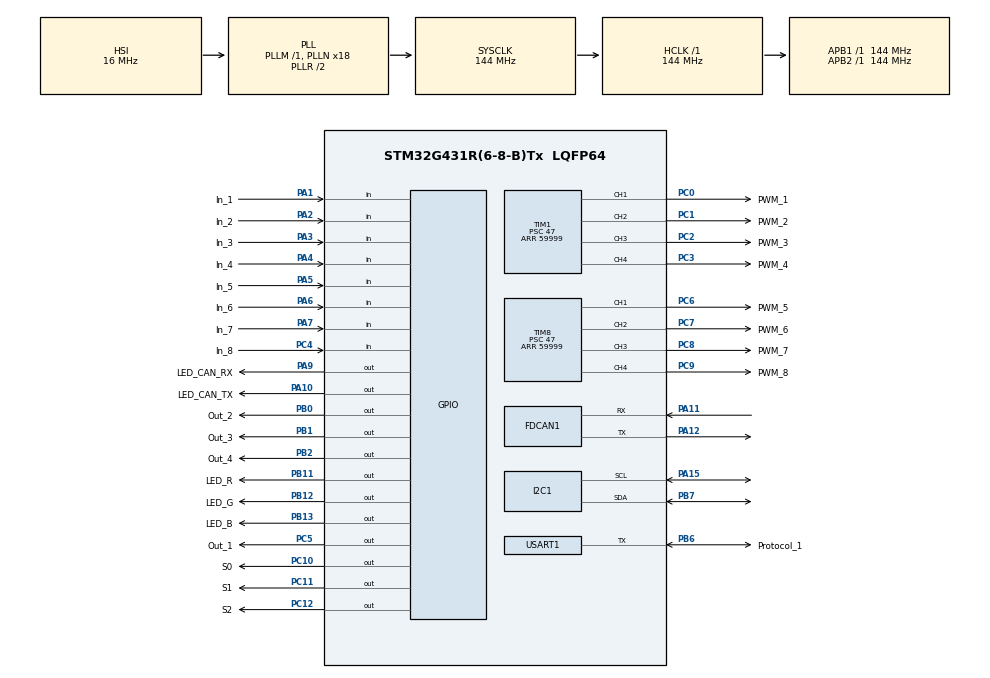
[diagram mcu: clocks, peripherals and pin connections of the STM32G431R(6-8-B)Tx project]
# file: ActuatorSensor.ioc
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Dma.Request0=USART1_RX
Dma.USART1_RX.0.Direction=DMA_PERIPH_TO_MEMORY
Dma.USART1_RX.0.EventEnable=DISABLE
Dma.USART1_RX.0.Instance=DMA1_Channel1
Dma.USART1_RX.0.MemDataAlignment=DMA_MDATAALIGN_BYTE
Dma.USART1_RX.0.MemInc=DMA_MINC_ENABLE
Dma.USART1_RX.0.Mode=DMA_NORMAL
Dma.USART1_RX.0.PeriphDataAlignment=DMA_PDATAALIGN_BYTE
Dma.USART1_RX.0.PeriphInc=DMA_PINC_DISABLE
Dma.USART1_RX.0.Polarity=HAL_DMAMUX_REQ_GEN_RISING
Dma.USART1_RX.0.Priority=DMA_PRIORITY_LOW
Dma.USART1_RX.0.RequestNumber=1
Dma.USART1_RX.0.SignalID=NONE
Dma.USART1_RX.0.SyncEnable=DISABLE
Dma.USART1_RX.0.SyncPolarity=HAL_DMAMUX_SYNC_NO_EVENT
Dma.USART1_RX.0.SyncRequestNumber=1
Dma.USART1_RX.0.SyncSignalID=NONE
FDCAN1.AutoRetransmission=ENABLE
FDCAN1.CalculateBaudRateNominal=1000000
FDCAN1.CalculateTimeBitNominal=1000
FDCAN1.CalculateTimeQuantumNominal=6.944444444444445
FDCAN1.DataPrescaler=1
FDCAN1.DataSyncJumpWidth=8
FDCAN1.DataTimeSeg1=9
FDCAN1.DataTimeSeg2=8
FDCAN1.FrameFormat=FDCAN_FRAME_FD_NO_BRS
FDCAN1.NominalPrescaler=1
FDCAN1.NominalSyncJumpWidth=19
FDCAN1.NominalTimeSeg1=124
FDCAN1.NominalTimeSeg2=19
FDCAN1.StdFiltersNbr=1
I2C1.Timing=0x20B0D9FF
Mcu.Family=STM32G4
Mcu.Name=STM32G431R(6-8-B)Tx
Mcu.Package=LQFP64
NVIC.DMA1_Channel1_IRQn=true\:0\:0\:false\:false\:true\:false\:true\:true
NVIC.FDCAN1_IT0_IRQn=true\:0\:0\:true\:false\:true\:true\:true\:true
NVIC.PriorityGroup=NVIC_PRIORITYGROUP_4
NVIC.TIM6_DAC_IRQn=true\:0\:0\:true\:false\:true\:true\:true\:true
NVIC.TIM7_IRQn=true\:0\:0\:true\:false\:true\:true\:true\:true
NVIC.USART1_IRQn=true\:0\:0\:false\:false\:true\:true\:true\:true
PA1.GPIO_Label=In_1
PA1.Signal=GPIO_Input
PA10.GPIO_Label=LED_CAN_TX
PA10.Signal=GPIO_Output
PA11.Mode=FDCAN_Activate
PA11.Signal=FDCAN1_RX
PA12.Mode=FDCAN_Activate
PA12.Signal=FDCAN1_TX
PA13.Mode=Trace_Asynchronous_SW
PA13.Signal=SYS_JTMS-SWDIO
PA14.Mode=Trace_Asynchronous_SW
PA14.Signal=SYS_JTCK-SWCLK
PA15.Mode=I2C
PA15.Signal=I2C1_SCL
PA2.GPIO_Label=In_2
PA2.Signal=GPIO_Input
PA3.GPIO_Label=In_3
PA3.Signal=GPIO_Input
PA4.GPIO_Label=In_4
PA4.Signal=GPIO_Input
PA5.GPIO_Label=In_5
PA5.Signal=GPIO_Input
PA6.GPIO_Label=In_6
PA6.Signal=GPIO_Input
PA7.GPIO_Label=In_7
PA7.Signal=GPIO_Input
PA9.GPIO_Label=LED_CAN_RX
PA9.Signal=GPIO_Output
PB0.GPIO_Label=Out_2
PB0.Signal=GPIO_Output
PB1.GPIO_Label=Out_3
PB1.Signal=GPIO_Output
PB11.GPIO_Label=LED_R
PB11.Signal=GPIO_Output
PB12.GPIO_Label=LED_G
PB12.Signal=GPIO_Output
PB13.GPIO_Label=LED_B
PB13.Signal=GPIO_Output
PB2.GPIO_Label=Out_4
PB2.Signal=GPIO_Output
PB3.Mode=Trace_Asynchronous_SW
PB3.Signal=SYS_JTDO-SWO
PB6.GPIO_Label=Protocol_1
PB6.GPIO_ModeDefaultOD=GPIO_MODE_AF_OD
PB6.GPIO_PuPd=GPIO_NOPULL
PB6.Mode=Half_duplex(single_wire_mode)
PB6.Signal=USART1_TX
PB7.Mode=I2C
PB7.Signal=I2C1_SDA
PC0.GPIO_Label=PWM_1
PC0.Signal=S_TIM1_CH1
PC1.GPIO_Label=PWM_2
PC1.Signal=S_TIM1_CH2
PC10.GPIO_Label=S0
PC10.Signal=GPIO_Output
PC11.GPIO_Label=S1
PC11.Signal=GPIO_Output
PC12.GPIO_Label=S2
PC12.Signal=GPIO_Output
PC2.GPIO_Label=PWM_3
PC2.Signal=S_TIM1_CH3
PC3.GPIO_Label=PWM_4
PC3.Signal=S_TIM1_CH4
PC4.GPIO_Label=In_8
PC4.Signal=GPIO_Input
PC5.GPIO_Label=Out_1
PC5.Signal=GPIO_Output
PC6.GPIO_Label=PWM_5
PC6.Signal=S_TIM8_CH1
PC7.GPIO_Label=PWM_6
PC7.Signal=S_TIM8_CH2
PC8.GPIO_Label=PWM_7
PC8.Signal=S_TIM8_CH3
PC9.GPIO_Label=PWM_8
PC9.Signal=S_TIM8_CH4
ProjectManager.HeapSize=0x200
ProjectManager.StackSize=0x400
ProjectManager.TargetToolchain=STM32CubeIDE
RCC.ADC12Freq_Value=144000000
RCC.AHBFreq_Value=144000000
RCC.APB1Freq_Value=144000000
RCC.APB1TimFreq_Value=144000000
RCC.APB2Freq_Value=144000000
RCC.APB2TimFreq_Value=144000000
RCC.CortexFreq_Value=144000000
RCC.EXTERNAL_CLOCK_VALUE=12288000
RCC.HCLKFreq_Value=144000000
RCC.HSE_VALUE=8000000
RCC.HSI48_VALUE=48000000
RCC.HSI_VALUE=16000000
RCC.LSE_VALUE=32768
RCC.PLLN=18
RCC.SYSCLKFreq_VALUE=144000000
RCC.SYSCLKSource=RCC_SYSCLKSOURCE_PLLCLK
RCC.USBFreq_Value=144000000
RCC.VCOOutputFreq_Value=288000000
SH.S_TIM1_CH1.0=TIM1_CH1,PWM Generation1 CH1
SH.S_TIM1_CH2.0=TIM1_CH2,PWM Generation2 CH2
SH.S_TIM1_CH3.0=TIM1_CH3,PWM Generation3 CH3
SH.S_TIM1_CH4.0=TIM1_CH4,PWM Generation4 CH4
SH.S_TIM8_CH1.0=TIM8_CH1,PWM Generation1 CH1
SH.S_TIM8_CH2.0=TIM8_CH2,PWM Generation2 CH2
SH.S_TIM8_CH3.0=TIM8_CH3,PWM Generation3 CH3
SH.S_TIM8_CH4.0=TIM8_CH4,PWM Generation4 CH4
TIM1.Channel-PWM\ Generation1\ CH1=TIM_CHANNEL_1
TIM1.Channel-PWM\ Generation2\ CH2=TIM_CHANNEL_2
TIM1.Channel-PWM\ Generation3\ CH3=TIM_CHANNEL_3
TIM1.Channel-PWM\ Generation4\ CH4=TIM_CHANNEL_4
TIM1.PeriodNoDither=59999
TIM1.Prescaler=47
TIM16.PeriodNoDither=47999
TIM16.Prescaler=5
TIM6.PeriodNoDither=59999
TIM6.Prescaler=23
TIM7.PeriodNoDither=59999
TIM8.Channel-PWM\ Generation1\ CH1=TIM_CHANNEL_1
TIM8.Channel-PWM\ Generation2\ CH2=TIM_CHANNEL_2
TIM8.Channel-PWM\ Generation3\ CH3=TIM_CHANNEL_3
TIM8.Channel-PWM\ Generation4\ CH4=TIM_CHANNEL_4
TIM8.PeriodNoDither=59999
TIM8.Prescaler=47
USART1.BaudRate=57600
USART1.VirtualMode-Half_duplex(single_wire_mode)=VM_ASYNC
VP_SYS_VS_DBSignals.Mode=DisableDeadBatterySignals
VP_TIM16_VS_ClockSourceINT.Mode=Enable_Timer
VP_TIM6_VS_ClockSourceINT.Mode=Enable_Timer
VP_TIM7_VS_ClockSourceINT.Mode=Enable_Timer
board=custom

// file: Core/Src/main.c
/* USER CODE BEGIN Header */
/**
  ******************************************************************************
  * @file           : main.c
  * @brief          : Main program body
  ******************************************************************************
  * @attention
  *
  * Copyright (c) 2024 STMicroelectronics.
  * All rights reserved.
  *
  * This software is licensed under terms that can be found in the LICENSE file
  * in the root directory of this software component.
  * If no LICENSE file comes with this software, it is provided AS-IS.
  *
  ******************************************************************************
  */
/* USER CODE END Header */
#include "main.h"

/* USER CODE BEGIN Includes */
//#include "rc_servo.h"
#include "ax_servo.h"
/* USER CODE END Includes */

FDCAN_HandleTypeDef hfdcan1;

I2C_HandleTypeDef hi2c1;

TIM_HandleTypeDef htim1;
TIM_HandleTypeDef htim6;
TIM_HandleTypeDef htim7;
TIM_HandleTypeDef htim8;
TIM_HandleTypeDef htim16;

UART_HandleTypeDef huart1;
DMA_HandleTypeDef hdma_usart1_rx;

void SystemClock_Config(void);
static void MX_GPIO_Init(void);
static void MX_DMA_Init(void);
static void MX_FDCAN1_Init(void);
static void MX_I2C1_Init(void);
static void MX_TIM1_Init(void);
static void MX_TIM8_Init(void);
static void MX_USART1_UART_Init(void);
static void MX_TIM6_Init(void);
static void MX_TIM7_Init(void);
static void MX_TIM16_Init(void);

int main(void)
{

  /* MCU Configuration--------------------------------------------------------*/

  /* Reset of all peripherals, Initializes the Flash interface and the Systick. */
  HAL_Init();

  /* Configure the system clock */
  SystemClock_Config();

  /* Initialize all configured peripherals */
  MX_GPIO_Init();
  MX_DMA_Init();
  MX_FDCAN1_Init();
  MX_I2C1_Init();
  MX_TIM1_Init();
  MX_TIM8_Init();
  MX_USART1_UART_Init();
  MX_TIM6_Init();
  MX_TIM7_Init();
  MX_TIM16_Init();
  /* USER CODE BEGIN 2 */
//  HAL_NVIC_SetPriority()
  FDCAN_Init(&hfdcan1);

  HAL_TIM_Base_Start_IT(&htim6); // Servo moving checking
  HAL_TIM_Base_Start_IT(&htim7); // Input pin states checking

//  Set_ADC_Channel(0);GRIPGRIP_GAIN_GAIN
//  HAL_ADCEx_Calibration_Start(&hadc1, ADC_SINGLE_ENDED);
//  HAL_ADC_Start_DMA(&hadc1, &adc_output, 1);

//  Init_RC_Servo(0, &htim1, TIM_CHANNEL_1);
//  Init_RC_Servo(1, &htim1, TIM_CHANNEL_2);
//  Init_RC_Servo(2, &htim1, TIM_CHANNEL_3);
//  Init_RC_Servo(3, &htim1, TIM_CHANNEL_4);
//
//  Init_RC_Servo(4, &htim8, TIM_CHANNEL_1);
//  Init_RC_Servo(5, &htim8, TIM_CHANNEL_2);
//  Init_RC_Servo(6, &htim8, TIM_CHANNEL_3);
//  Init_RC_Servo(7, &htim8, TIM_CHANNEL_4);

  /* USER CODE END 2 */

  /* Infinite loop */
  /* USER CODE BEGIN WHILE */
//  uint8_t some_status = 0;
  while (1)
  {
//	if (send_status == HAL_OK)
//	{
//	  send_status = HAL_ERROR;
//	  HAL_GPIO_TogglePin(LED_CAN_TX_GPIO_Port, LED_CAN_TX_Pin);
//	  some_status = 1;
//	}
//	else
//	{
//	  HAL_GPIO_WritePin(LED_CAN_TX_GPIO_Port, LED_CAN_TX_Pin, GPIO_PIN_RESET);
//	}
//
//	if (receive_status == HAL_OK)
//	{
//	  receive_status = HAL_ERROR;
//	  HAL_GPIO_TogglePin(LED_CAN_RX_GPIO_Port, LED_CAN_RX_Pin);
//	  some_status = 1;
//	}
//	else
//	{
//      HAL_GPIO_WritePin(LED_CAN_RX_GPIO_Port, LED_CAN_RX_Pin, GPIO_PIN_RESET);
//	}
//
//	if (some_status)
//	{
//	  some_status = 0;
//	  HAL_Delay(50);
//	}
//	  HAL_Delay(1000);
//
//	  Set_Angle(id, 0);
//
//	  HAL_Delay(1000);
//	if (rx_set) {
//		rx_set = 0;
//		HAL_Delay(500);
//		HAL_GPIO_WritePin(LED_G_GPIO_Port, LED_G_Pin, GPIO_PIN_RESET);
//	}
    /* USER CODE END WHILE */

  }
}

void SystemClock_Config(void)
{
  RCC_OscInitTypeDef RCC_OscInitStruct = {0};
  RCC_ClkInitTypeDef RCC_ClkInitStruct = {0};

  /** Configure the main internal regulator output voltage
  */
  HAL_PWREx_ControlVoltageScaling(PWR_REGULATOR_VOLTAGE_SCALE1);

  /** Initializes the RCC Oscillators according to the specified parameters
  * in the RCC_OscInitTypeDef structure.
  */
  RCC_OscInitStruct.OscillatorType = RCC_OSCILLATORTYPE_HSI;
  RCC_OscInitStruct.HSIState = RCC_HSI_ON;
  RCC_OscInitStruct.HSICalibrationValue = RCC_HSICALIBRATION_DEFAULT;
  RCC_OscInitStruct.PLL.PLLState = RCC_PLL_ON;
  RCC_OscInitStruct.PLL.PLLSource = RCC_PLLSOURCE_HSI;
  RCC_OscInitStruct.PLL.PLLM = RCC_PLLM_DIV1;
  RCC_OscInitStruct.PLL.PLLN = 18;
  RCC_OscInitStruct.PLL.PLLP = RCC_PLLP_DIV2;
  RCC_OscInitStruct.PLL.PLLQ = RCC_PLLQ_DIV2;
  RCC_OscInitStruct.PLL.PLLR = RCC_PLLR_DIV2;
  if (HAL_RCC_OscConfig(&RCC_OscInitStruct) != HAL_OK)
  {
    Error_Handler();
  }

  /** Initializes the CPU, AHB and APB buses clocks
  */
  RCC_ClkInitStruct.ClockType = RCC_CLOCKTYPE_HCLK|RCC_CLOCKTYPE_SYSCLK
                              |RCC_CLOCKTYPE_PCLK1|RCC_CLOCKTYPE_PCLK2;
  RCC_ClkInitStruct.SYSCLKSource = RCC_SYSCLKSOURCE_PLLCLK;
  RCC_ClkInitStruct.AHBCLKDivider = RCC_SYSCLK_DIV1;
  RCC_ClkInitStruct.APB1CLKDivider = RCC_HCLK_DIV1;
  RCC_ClkInitStruct.APB2CLKDivider = RCC_HCLK_DIV1;

  if (HAL_RCC_ClockConfig(&RCC_ClkInitStruct, FLASH_LATENCY_4) != HAL_OK)
  {
    Error_Handler();
  }
}

static void MX_FDCAN1_Init(void)
{

  hfdcan1.Instance = FDCAN1;
  hfdcan1.Init.ClockDivider = FDCAN_CLOCK_DIV1;
  hfdcan1.Init.FrameFormat = FDCAN_FRAME_FD_NO_BRS;
  hfdcan1.Init.Mode = FDCAN_MODE_NORMAL;
  hfdcan1.Init.AutoRetransmission = ENABLE;
  hfdcan1.Init.TransmitPause = DISABLE;
  hfdcan1.Init.ProtocolException = DISABLE;
  hfdcan1.Init.NominalPrescaler = 1;
  hfdcan1.Init.NominalSyncJumpWidth = 19;
  hfdcan1.Init.NominalTimeSeg1 = 124;
  hfdcan1.Init.NominalTimeSeg2 = 19;
  hfdcan1.Init.DataPrescaler = 1;
  hfdcan1.Init.DataSyncJumpWidth = 8;
  hfdcan1.Init.DataTimeSeg1 = 9;
  hfdcan1.Init.DataTimeSeg2 = 8;
  hfdcan1.Init.StdFiltersNbr = 1;
  hfdcan1.Init.ExtFiltersNbr = 0;
  hfdcan1.Init.TxFifoQueueMode = FDCAN_TX_FIFO_OPERATION;
  if (HAL_FDCAN_Init(&hfdcan1) != HAL_OK)
  {
    Error_Handler();
  }

}

static void MX_I2C1_Init(void)
{

  hi2c1.Instance = I2C1;
  hi2c1.Init.Timing = 0x20B0D9FF;
  hi2c1.Init.OwnAddress1 = 0;
  hi2c1.Init.AddressingMode = I2C_ADDRESSINGMODE_7BIT;
  hi2c1.Init.DualAddressMode = I2C_DUALADDRESS_DISABLE;
  hi2c1.Init.OwnAddress2 = 0;
  hi2c1.Init.OwnAddress2Masks = I2C_OA2_NOMASK;
  hi2c1.Init.GeneralCallMode = I2C_GENERALCALL_DISABLE;
  hi2c1.Init.NoStretchMode = I2C_NOSTRETCH_DISABLE;
  if (HAL_I2C_Init(&hi2c1) != HAL_OK)
  {
    Error_Handler();
  }

  /** Configure Analogue filter
  */
  if (HAL_I2CEx_ConfigAnalogFilter(&hi2c1, I2C_ANALOGFILTER_ENABLE) != HAL_OK)
  {
    Error_Handler();
  }

  /** Configure Digital filter
  */
  if (HAL_I2CEx_ConfigDigitalFilter(&hi2c1, 0) != HAL_OK)
  {
    Error_Handler();
  }

}

static void MX_TIM1_Init(void)
{

  TIM_MasterConfigTypeDef sMasterConfig = {0};
  TIM_OC_InitTypeDef sConfigOC = {0};
  TIM_BreakDeadTimeConfigTypeDef sBreakDeadTimeConfig = {0};

  htim1.Instance = TIM1;
  htim1.Init.Prescaler = 47;
  htim1.Init.CounterMode = TIM_COUNTERMODE_UP;
  htim1.Init.Period = 59999;
  htim1.Init.ClockDivision = TIM_CLOCKDIVISION_DIV1;
  htim1.Init.RepetitionCounter = 0;
  htim1.Init.AutoReloadPreload = TIM_AUTORELOAD_PRELOAD_DISABLE;
  if (HAL_TIM_PWM_Init(&htim1) != HAL_OK)
  {
    Error_Handler();
  }
  sMasterConfig.MasterOutputTrigger = TIM_TRGO_RESET;
  sMasterConfig.MasterOutputTrigger2 = TIM_TRGO2_RESET;
  sMasterConfig.MasterSlaveMode = TIM_MASTERSLAVEMODE_DISABLE;
  if (HAL_TIMEx_MasterConfigSynchronization(&htim1, &sMasterConfig) != HAL_OK)
  {
    Error_Handler();
  }
  sConfigOC.OCMode = TIM_OCMODE_PWM1;
  sConfigOC.Pulse = 0;
  sConfigOC.OCPolarity = TIM_OCPOLARITY_HIGH;
  sConfigOC.OCNPolarity = TIM_OCNPOLARITY_HIGH;
  sConfigOC.OCFastMode = TIM_OCFAST_DISABLE;
  sConfigOC.OCIdleState = TIM_OCIDLESTATE_RESET;
  sConfigOC.OCNIdleState = TIM_OCNIDLESTATE_RESET;
  if (HAL_TIM_PWM_ConfigChannel(&htim1, &sConfigOC, TIM_CHANNEL_1) != HAL_OK)
  {
    Error_Handler();
  }
  if (HAL_TIM_PWM_ConfigChannel(&htim1, &sConfigOC, TIM_CHANNEL_2) != HAL_OK)
  {
    Error_Handler();
  }
  if (HAL_TIM_PWM_ConfigChannel(&htim1, &sConfigOC, TIM_CHANNEL_3) != HAL_OK)
  {
    Error_Handler();
  }
  if (HAL_TIM_PWM_ConfigChannel(&htim1, &sConfigOC, TIM_CHANNEL_4) != HAL_OK)
  {
    Error_Handler();
  }
  sBreakDeadTimeConfig.OffStateRunMode = TIM_OSSR_DISABLE;
  sBreakDeadTimeConfig.OffStateIDLEMode = TIM_OSSI_DISABLE;
  sBreakDeadTimeConfig.LockLevel = TIM_LOCKLEVEL_OFF;
  sBreakDeadTimeConfig.DeadTime = 0;
  sBreakDeadTimeConfig.BreakState = TIM_BREAK_DISABLE;
  sBreakDeadTimeConfig.BreakPolarity = TIM_BREAKPOLARITY_HIGH;
  sBreakDeadTimeConfig.BreakFilter = 0;
  sBreakDeadTimeConfig.BreakAFMode = TIM_BREAK_AFMODE_INPUT;
  sBreakDeadTimeConfig.Break2State = TIM_BREAK2_DISABLE;
  sBreakDeadTimeConfig.Break2Polarity = TIM_BREAK2POLARITY_HIGH;
  sBreakDeadTimeConfig.Break2Filter = 0;
  sBreakDeadTimeConfig.Break2AFMode = TIM_BREAK_AFMODE_INPUT;
  sBreakDeadTimeConfig.AutomaticOutput = TIM_AUTOMATICOUTPUT_DISABLE;
  if (HAL_TIMEx_ConfigBreakDeadTime(&htim1, &sBreakDeadTimeConfig) != HAL_OK)
  {
    Error_Handler();
  }
  HAL_TIM_MspPostInit(&htim1);

}

static void MX_TIM6_Init(void)
{

  TIM_MasterConfigTypeDef sMasterConfig = {0};

  htim6.Instance = TIM6;
  htim6.Init.Prescaler = 23;
  htim6.Init.CounterMode = TIM_COUNTERMODE_UP;
  htim6.Init.Period = 59999;
  htim6.Init.AutoReloadPreload = TIM_AUTORELOAD_PRELOAD_DISABLE;
  if (HAL_TIM_Base_Init(&htim6) != HAL_OK)
  {
    Error_Handler();
  }
  sMasterConfig.MasterOutputTrigger = TIM_TRGO_RESET;
  sMasterConfig.MasterSlaveMode = TIM_MASTERSLAVEMODE_DISABLE;
  if (HAL_TIMEx_MasterConfigSynchronization(&htim6, &sMasterConfig) != HAL_OK)
  {
    Error_Handler();
  }

}

static void MX_TIM7_Init(void)
{

  TIM_MasterConfigTypeDef sMasterConfig = {0};

  htim7.Instance = TIM7;
  htim7.Init.Prescaler = 0;
  htim7.Init.CounterMode = TIM_COUNTERMODE_UP;
  htim7.Init.Period = 59999;
  htim7.Init.AutoReloadPreload = TIM_AUTORELOAD_PRELOAD_DISABLE;
  if (HAL_TIM_Base_Init(&htim7) != HAL_OK)
  {
    Error_Handler();
  }
  sMasterConfig.MasterOutputTrigger = TIM_TRGO_RESET;
  sMasterConfig.MasterSlaveMode = TIM_MASTERSLAVEMODE_DISABLE;
  if (HAL_TIMEx_MasterConfigSynchronization(&htim7, &sMasterConfig) != HAL_OK)
  {
    Error_Handler();
  }

}

static void MX_TIM8_Init(void)
{

  TIM_MasterConfigTypeDef sMasterConfig = {0};
  TIM_OC_InitTypeDef sConfigOC = {0};
  TIM_BreakDeadTimeConfigTypeDef sBreakDeadTimeConfig = {0};

  htim8.Instance = TIM8;
  htim8.Init.Prescaler = 47;
  htim8.Init.CounterMode = TIM_COUNTERMODE_UP;
  htim8.Init.Period = 59999;
  htim8.Init.ClockDivision = TIM_CLOCKDIVISION_DIV1;
  htim8.Init.RepetitionCounter = 0;
  htim8.Init.AutoReloadPreload = TIM_AUTORELOAD_PRELOAD_DISABLE;
  if (HAL_TIM_PWM_Init(&htim8) != HAL_OK)
  {
    Error_Handler();
  }
  sMasterConfig.MasterOutputTrigger = TIM_TRGO_RESET;
  sMasterConfig.MasterOutputTrigger2 = TIM_TRGO2_RESET;
  sMasterConfig.MasterSlaveMode = TIM_MASTERSLAVEMODE_DISABLE;
  if (HAL_TIMEx_MasterConfigSynchronization(&htim8, &sMasterConfig) != HAL_OK)
  {
    Error_Handler();
  }
  sConfigOC.OCMode = TIM_OCMODE_PWM1;
  sConfigOC.Pulse = 0;
  sConfigOC.OCPolarity = TIM_OCPOLARITY_HIGH;
  sConfigOC.OCNPolarity = TIM_OCNPOLARITY_HIGH;
  sConfigOC.OCFastMode = TIM_OCFAST_DISABLE;
  sConfigOC.OCIdleState = TIM_OCIDLESTATE_RESET;
  sConfigOC.OCNIdleState = TIM_OCNIDLESTATE_RESET;
  if (HAL_TIM_PWM_ConfigChannel(&htim8, &sConfigOC, TIM_CHANNEL_1) != HAL_OK)
  {
    Error_Handler();
  }
  if (HAL_TIM_PWM_ConfigChannel(&htim8, &sConfigOC, TIM_CHANNEL_2) != HAL_OK)
  {
    Error_Handler();
  }
  if (HAL_TIM_PWM_ConfigChannel(&htim8, &sConfigOC, TIM_CHANNEL_3) != HAL_OK)
  {
    Error_Handler();
  }
  if (HAL_TIM_PWM_ConfigChannel(&htim8, &sConfigOC, TIM_CHANNEL_4) != HAL_OK)
  {
    Error_Handler();
  }
  sBreakDeadTimeConfig.OffStateRunMode = TIM_OSSR_DISABLE;
  sBreakDeadTimeConfig.OffStateIDLEMode = TIM_OSSI_DISABLE;
  sBreakDeadTimeConfig.LockLevel = TIM_LOCKLEVEL_OFF;
  sBreakDeadTimeConfig.DeadTime = 0;
  sBreakDeadTimeConfig.BreakState = TIM_BREAK_DISABLE;
  sBreakDeadTimeConfig.BreakPolarity = TIM_BREAKPOLARITY_HIGH;
  sBreakDeadTimeConfig.BreakFilter = 0;
  sBreakDeadTimeConfig.BreakAFMode = TIM_BREAK_AFMODE_INPUT;
  sBreakDeadTimeConfig.Break2State = TIM_BREAK2_DISABLE;
  sBreakDeadTimeConfig.Break2Polarity = TIM_BREAK2POLARITY_HIGH;
  sBreakDeadTimeConfig.Break2Filter = 0;
  sBreakDeadTimeConfig.Break2AFMode = TIM_BREAK_AFMODE_INPUT;
  sBreakDeadTimeConfig.AutomaticOutput = TIM_AUTOMATICOUTPUT_DISABLE;
  if (HAL_TIMEx_ConfigBreakDeadTime(&htim8, &sBreakDeadTimeConfig) != HAL_OK)
  {
    Error_Handler();
  }
  HAL_TIM_MspPostInit(&htim8);

}

static void MX_TIM16_Init(void)
{

  htim16.Instance = TIM16;
  htim16.Init.Prescaler = 5;
  htim16.Init.CounterMode = TIM_COUNTERMODE_UP;
  htim16.Init.Period = 47999;
  htim16.Init.ClockDivision = TIM_CLOCKDIVISION_DIV1;
  htim16.Init.RepetitionCounter = 0;
  htim16.Init.AutoReloadPreload = TIM_AUTORELOAD_PRELOAD_DISABLE;
  if (HAL_TIM_Base_Init(&htim16) != HAL_OK)
  {
    Error_Handler();
  }

}

static void MX_USART1_UART_Init(void)
{

  huart1.Instance = USART1;
  huart1.Init.BaudRate = 57600;
  huart1.Init.WordLength = UART_WORDLENGTH_8B;
  huart1.Init.StopBits = UART_STOPBITS_1;
  huart1.Init.Parity = UART_PARITY_NONE;
  huart1.Init.Mode = UART_MODE_TX_RX;
  huart1.Init.HwFlowCtl = UART_HWCONTROL_NONE;
  huart1.Init.OverSampling = UART_OVERSAMPLING_16;
  huart1.Init.OneBitSampling = UART_ONE_BIT_SAMPLE_DISABLE;
  huart1.Init.ClockPrescaler = UART_PRESCALER_DIV1;
  huart1.AdvancedInit.AdvFeatureInit = UART_ADVFEATURE_NO_INIT;
  if (HAL_HalfDuplex_Init(&huart1) != HAL_OK)
  {
    Error_Handler();
  }
  if (HAL_UARTEx_SetTxFifoThreshold(&huart1, UART_TXFIFO_THRESHOLD_1_8) != HAL_OK)
  {
    Error_Handler();
  }
  if (HAL_UARTEx_SetRxFifoThreshold(&huart1, UART_RXFIFO_THRESHOLD_1_8) != HAL_OK)
  {
    Error_Handler();
  }
  if (HAL_UARTEx_DisableFifoMode(&huart1) != HAL_OK)
  {
    Error_Handler();
  }

}

static void MX_DMA_Init(void)
{

  /* DMA controller clock enable */
  __HAL_RCC_DMAMUX1_CLK_ENABLE();
  __HAL_RCC_DMA1_CLK_ENABLE();

  /* DMA interrupt init */
  /* DMA1_Channel1_IRQn interrupt configuration */
  HAL_NVIC_SetPriority(DMA1_Channel1_IRQn, 0, 0);
  HAL_NVIC_EnableIRQ(DMA1_Channel1_IRQn);

}

static void MX_GPIO_Init(void)
{
  GPIO_InitTypeDef GPIO_InitStruct = {0};

  /* GPIO Ports Clock Enable */
  __HAL_RCC_GPIOC_CLK_ENABLE();
  __HAL_RCC_GPIOA_CLK_ENABLE();
  __HAL_RCC_GPIOB_CLK_ENABLE();

  /*Configure GPIO pin Output Level */
  HAL_GPIO_WritePin(GPIOC, Out_1_Pin|S0_Pin|S1_Pin|S2_Pin, GPIO_PIN_RESET);

  /*Configure GPIO pin Output Level */
  HAL_GPIO_WritePin(GPIOB, Out_2_Pin|Out_3_Pin|Out_4_Pin|LED_R_Pin
                          |LED_G_Pin|LED_B_Pin, GPIO_PIN_RESET);

  /*Configure GPIO pin Output Level */
  HAL_GPIO_WritePin(GPIOA, LED_CAN_RX_Pin|LED_CAN_TX_Pin, GPIO_PIN_RESET);

  /*Configure GPIO pins : In_1_Pin In_2_Pin In_3_Pin In_4_Pin
                           In_5_Pin In_6_Pin In_7_Pin */
  GPIO_InitStruct.Pin = In_1_Pin|In_2_Pin|In_3_Pin|In_4_Pin
                          |In_5_Pin|In_6_Pin|In_7_Pin;
  GPIO_InitStruct.Mode = GPIO_MODE_INPUT;
  GPIO_InitStruct.Pull = GPIO_NOPULL;
  HAL_GPIO_Init(GPIOA, &GPIO_InitStruct);

  /*Configure GPIO pin : In_8_Pin */
  GPIO_InitStruct.Pin = In_8_Pin;
  GPIO_InitStruct.Mode = GPIO_MODE_INPUT;
  GPIO_InitStruct.Pull = GPIO_NOPULL;
  HAL_GPIO_Init(In_8_GPIO_Port, &GPIO_InitStruct);

  /*Configure GPIO pins : Out_1_Pin S0_Pin S1_Pin S2_Pin */
  GPIO_InitStruct.Pin = Out_1_Pin|S0_Pin|S1_Pin|S2_Pin;
  GPIO_InitStruct.Mode = GPIO_MODE_OUTPUT_PP;
  GPIO_InitStruct.Pull = GPIO_NOPULL;
  GPIO_InitStruct.Speed = GPIO_SPEED_FREQ_LOW;
  HAL_GPIO_Init(GPIOC, &GPIO_InitStruct);

  /*Configure GPIO pins : Out_2_Pin Out_3_Pin Out_4_Pin LED_R_Pin
                           LED_G_Pin LED_B_Pin */
  GPIO_InitStruct.Pin = Out_2_Pin|Out_3_Pin|Out_4_Pin|LED_R_Pin
                          |LED_G_Pin|LED_B_Pin;
  GPIO_InitStruct.Mode = GPIO_MODE_OUTPUT_PP;
  GPIO_InitStruct.Pull = GPIO_NOPULL;
  GPIO_InitStruct.Speed = GPIO_SPEED_FREQ_LOW;
  HAL_GPIO_Init(GPIOB, &GPIO_InitStruct);

  /*Configure GPIO pins : LED_CAN_RX_Pin LED_CAN_TX_Pin */
  GPIO_InitStruct.Pin = LED_CAN_RX_Pin|LED_CAN_TX_Pin;
  GPIO_InitStruct.Mode = GPIO_MODE_OUTPUT_PP;
  GPIO_InitStruct.Pull = GPIO_NOPULL;
  GPIO_InitStruct.Speed = GPIO_SPEED_FREQ_LOW;
  HAL_GPIO_Init(GPIOA, &GPIO_InitStruct);

}

void Error_Handler(void)
{
  /* USER CODE BEGIN Error_Handler_Debug */
  HAL_GPIO_WritePin(LED_R_GPIO_Port, LED_R_Pin, GPIO_PIN_SET);

  /* User can add his own implementation to report the HAL error return state */
  __disable_irq();
  while (1)
  {
  }
  /* USER CODE END Error_Handler_Debug */
}
